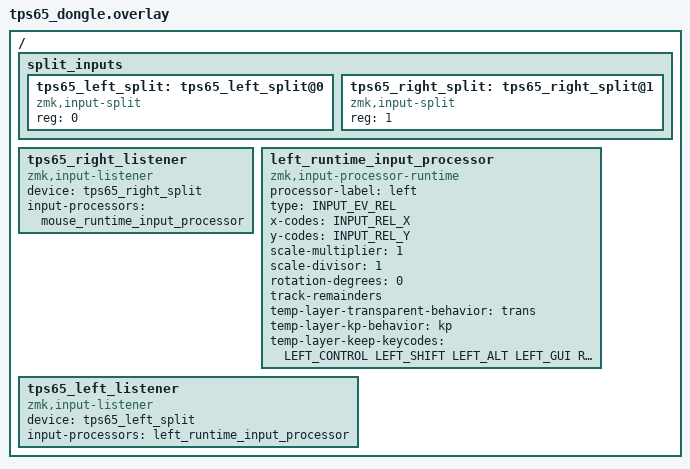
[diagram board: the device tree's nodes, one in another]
/*
 * Dongle side of the TPS65 trackpads (tasks 04, 07).
 * The right half sends pad movement over the split link as input-split reg 1
 * (same reg as tps65_right_split in tps65_right.overlay), the left half as
 * reg 0 (tps65_left_split in tps65_left_aym.overlay). Both become cursor
 * movement for now; the left pad turns into scroll in task 08.
 *
 * Speed, rotation and axis direction: the runtime input processor
 * (cormoran module, already on in the dongle .conf), changeable at run time
 * without a new build. Its includes come from eyelash_sofle_central_dongle.overlay.
 */

#include <zephyr/dt-bindings/input/input-event-codes.h>
#include <dt-bindings/zmk/keys.h>

/ {
    split_inputs {
        #address-cells = <1>;
        #size-cells = <0>;

        tps65_left_split: tps65_left_split@0 {
            compatible = "zmk,input-split";
            reg = <0>;
        };

        tps65_right_split: tps65_right_split@1 {
            compatible = "zmk,input-split";
            reg = <1>;
        };
    };

    tps65_right_listener: tps65_right_listener {
        compatible = "zmk,input-listener";
        device = <&tps65_right_split>;
        input-processors = <&mouse_runtime_input_processor>;
    };

    /* Left pad: its own runtime processor, same defaults as "mouse", so its
     * settings (and later XY-to-scroll, axis invert) change apart from the right pad.
     */
    left_runtime_input_processor: left_runtime_input_processor {
        compatible = "zmk,input-processor-runtime";
        processor-label = "left";
        type = <INPUT_EV_REL>;
        x-codes = <INPUT_REL_X>;
        y-codes = <INPUT_REL_Y>;
        scale-multiplier = <1>;
        scale-divisor = <1>;
        rotation-degrees = <0>;
        track-remainders;

        temp-layer-transparent-behavior = <&trans>;
        temp-layer-kp-behavior = <&kp>;
        temp-layer-keep-keycodes = <LEFT_CONTROL LEFT_SHIFT LEFT_ALT LEFT_GUI RIGHT_CONTROL RIGHT_SHIFT RIGHT_ALT RIGHT_GUI>;

        #input-processor-cells = <0>;
    };

    tps65_left_listener: tps65_left_listener {
        compatible = "zmk,input-listener";
        device = <&tps65_left_split>;
        input-processors = <&left_runtime_input_processor>;
    };
};
